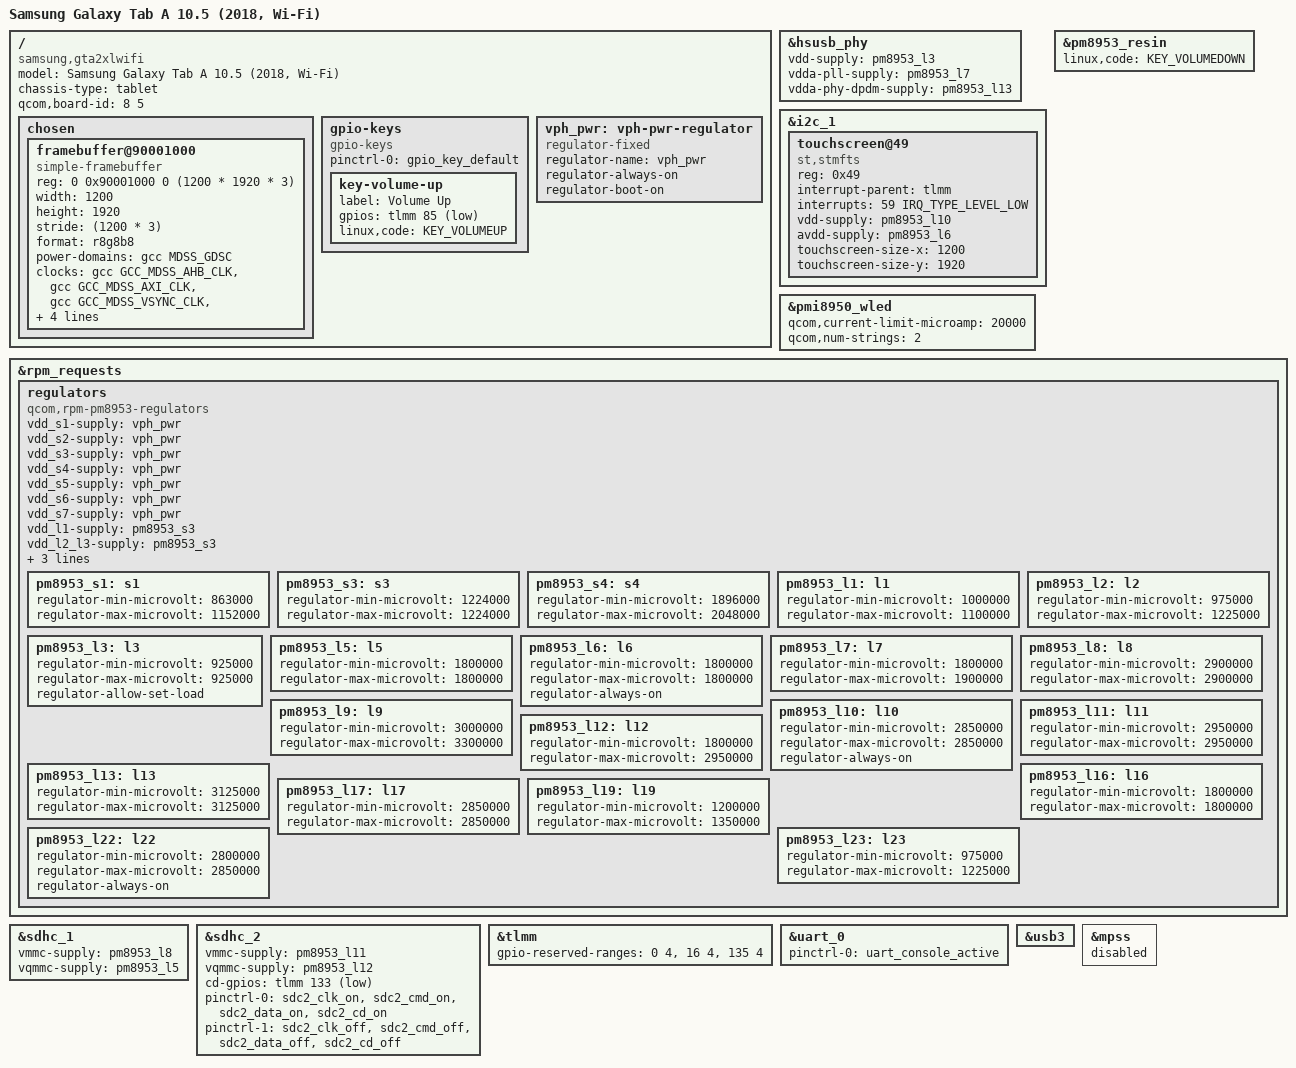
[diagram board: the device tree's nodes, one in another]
// SPDX-License-Identifier: GPL-2.0-only
/*
 * Samsung Galaxy Tab A 10.5 (2018, Wi-Fi) — "gta2xlwifi"
 * SoC: Qualcomm SDM450 / MSM8953 family
 *
 * Initial mainline device tree. Values ported from the downstream
 * Android dts (arch/arm/boot/dts/samsung/sdm450/*gta2xlwifi*).
 * Sections marked TODO still need verification on real hardware.
 */

/dts-v1/;

#include "msm8953.dtsi"
#include "pm8953.dtsi"
#include "pmi8950.dtsi"

/ {
	model = "Samsung Galaxy Tab A 10.5 (2018, Wi-Fi)";
	compatible = "samsung,gta2xlwifi", "qcom,msm8953";
	chassis-type = "tablet";

	/* TODO: confirm against lk2nd; downstream used qcom,board-id = <8 5> */
	qcom,board-id = <8 5>;

	chosen {
		#address-cells = <2>;
		#size-cells = <2>;
		ranges;

		/*
		 * Continuous splash framebuffer set up by the bootloader.
		 * Panel is 1200x1920 (WUXGA, Himax HX8279 TV101WUM).
		 * TODO: verify base address from lk2nd / downstream cont_splash.
		 */
		framebuffer@90001000 {
			compatible = "simple-framebuffer";
			reg = <0 0x90001000 0 (1200 * 1920 * 3)>;

			width = <1200>;
			height = <1920>;
			stride = <(1200 * 3)>;
			format = "r8g8b8";

			power-domains = <&gcc MDSS_GDSC>;

			clocks = <&gcc GCC_MDSS_AHB_CLK>,
				 <&gcc GCC_MDSS_AXI_CLK>,
				 <&gcc GCC_MDSS_VSYNC_CLK>,
				 <&gcc GCC_MDSS_MDP_CLK>,
				 <&gcc GCC_MDSS_BYTE0_CLK>,
				 <&gcc GCC_MDSS_PCLK0_CLK>,
				 <&gcc GCC_MDSS_ESC0_CLK>;
		};
	};

	gpio-keys {
		compatible = "gpio-keys";

		pinctrl-names = "default";
		pinctrl-0 = <&gpio_key_default>;

		key-volume-up {
			label = "Volume Up";
			gpios = <&tlmm 85 GPIO_ACTIVE_LOW>;
			linux,code = <KEY_VOLUMEUP>;
		};
		/* Volume Down and Power are handled by the PMIC (see &pm8953_resin
		 * and the pm8953 pon below) */
	};

	vph_pwr: vph-pwr-regulator {
		compatible = "regulator-fixed";
		regulator-name = "vph_pwr";
		regulator-always-on;
		regulator-boot-on;
	};
};

&hsusb_phy {
	vdd-supply = <&pm8953_l3>;
	vdda-pll-supply = <&pm8953_l7>;
	vdda-phy-dpdm-supply = <&pm8953_l13>;

	status = "okay";
};

/* Touchscreen: STMicroelectronics FTS, i2c@78b5000, addr 0x49, IRQ on tlmm 59 */
&i2c_1 {
	status = "okay";

	touchscreen@49 {
		compatible = "st,stmfts";
		reg = <0x49>;

		interrupt-parent = <&tlmm>;
		interrupts = <59 IRQ_TYPE_LEVEL_LOW>;

		/* TODO: confirm regulator rails (downstream: tsp_avdd ~2.9V, tsp_dvdd 1.8V) */
		vdd-supply = <&pm8953_l10>;
		avdd-supply = <&pm8953_l6>;

		touchscreen-size-x = <1200>;
		touchscreen-size-y = <1920>;
	};
};

/* Volume Down */
&pm8953_resin {
	linux,code = <KEY_VOLUMEDOWN>;
	status = "okay";
};

/* Display backlight (WLED) */
&pmi8950_wled {
	qcom,current-limit-microamp = <20000>;
	qcom,num-strings = <2>;

	status = "okay";
};

&rpm_requests {
	regulators {
		compatible = "qcom,rpm-pm8953-regulators";

		vdd_s1-supply = <&vph_pwr>;
		vdd_s2-supply = <&vph_pwr>;
		vdd_s3-supply = <&vph_pwr>;
		vdd_s4-supply = <&vph_pwr>;
		vdd_s5-supply = <&vph_pwr>;
		vdd_s6-supply = <&vph_pwr>;
		vdd_s7-supply = <&vph_pwr>;
		vdd_l1-supply = <&pm8953_s3>;
		vdd_l2_l3-supply = <&pm8953_s3>;
		vdd_l4_l5_l6_l7_l16_l19-supply = <&pm8953_s4>;
		vdd_l8_l11_l12_l13_l14_l15-supply = <&vph_pwr>;
		vdd_l9_l10_l17_l18_l22-supply = <&vph_pwr>;

		pm8953_s1: s1 {
			regulator-min-microvolt = <863000>;
			regulator-max-microvolt = <1152000>;
		};

		pm8953_s3: s3 {
			regulator-min-microvolt = <1224000>;
			regulator-max-microvolt = <1224000>;
		};

		pm8953_s4: s4 {
			regulator-min-microvolt = <1896000>;
			regulator-max-microvolt = <2048000>;
		};

		pm8953_l1: l1 {
			regulator-min-microvolt = <1000000>;
			regulator-max-microvolt = <1100000>;
		};

		pm8953_l2: l2 {
			regulator-min-microvolt = <975000>;
			regulator-max-microvolt = <1225000>;
		};

		pm8953_l3: l3 {
			regulator-min-microvolt = <925000>;
			regulator-max-microvolt = <925000>;
			regulator-allow-set-load;
		};

		pm8953_l5: l5 {
			regulator-min-microvolt = <1800000>;
			regulator-max-microvolt = <1800000>;
		};

		pm8953_l6: l6 {
			regulator-min-microvolt = <1800000>;
			regulator-max-microvolt = <1800000>;
			regulator-always-on;
		};

		pm8953_l7: l7 {
			regulator-min-microvolt = <1800000>;
			regulator-max-microvolt = <1900000>;
		};

		pm8953_l8: l8 {
			regulator-min-microvolt = <2900000>;
			regulator-max-microvolt = <2900000>;
		};

		pm8953_l9: l9 {
			regulator-min-microvolt = <3000000>;
			regulator-max-microvolt = <3300000>;
		};

		pm8953_l10: l10 {
			regulator-min-microvolt = <2850000>;
			regulator-max-microvolt = <2850000>;
			regulator-always-on;
		};

		pm8953_l11: l11 {
			regulator-min-microvolt = <2950000>;
			regulator-max-microvolt = <2950000>;
		};

		pm8953_l12: l12 {
			regulator-min-microvolt = <1800000>;
			regulator-max-microvolt = <2950000>;
		};

		pm8953_l13: l13 {
			regulator-min-microvolt = <3125000>;
			regulator-max-microvolt = <3125000>;
		};

		pm8953_l16: l16 {
			regulator-min-microvolt = <1800000>;
			regulator-max-microvolt = <1800000>;
		};

		pm8953_l17: l17 {
			regulator-min-microvolt = <2850000>;
			regulator-max-microvolt = <2850000>;
		};

		pm8953_l19: l19 {
			regulator-min-microvolt = <1200000>;
			regulator-max-microvolt = <1350000>;
		};

		pm8953_l22: l22 {
			regulator-min-microvolt = <2800000>;
			regulator-max-microvolt = <2850000>;
			regulator-always-on;
		};

		pm8953_l23: l23 {
			regulator-min-microvolt = <975000>;
			regulator-max-microvolt = <1225000>;
		};
	};
};

/* eMMC */
&sdhc_1 {
	vmmc-supply = <&pm8953_l8>;
	vqmmc-supply = <&pm8953_l5>;

	status = "okay";
};

/* microSD */
&sdhc_2 {
	vmmc-supply = <&pm8953_l11>;
	vqmmc-supply = <&pm8953_l12>;

	/* TODO: confirm card-detect GPIO for this board */
	cd-gpios = <&tlmm 133 GPIO_ACTIVE_LOW>;

	pinctrl-names = "default", "sleep";
	pinctrl-0 = <&sdc2_clk_on &sdc2_cmd_on &sdc2_data_on &sdc2_cd_on>;
	pinctrl-1 = <&sdc2_clk_off &sdc2_cmd_off &sdc2_data_off &sdc2_cd_off>;

	status = "okay";
};

&tlmm {
	gpio-reserved-ranges = <0 4>, <16 4>, <135 4>;
};

/* Serial console (via lk2nd) */
&uart_0 {
	pinctrl-names = "default";
	pinctrl-0 = <&uart_console_active>;

	status = "okay";
};

&usb3 {
	/* Node already defaults to peripheral via role-switch-default-mode */
	status = "okay";
};

/*
 * Wi-Fi only tablet — no cellular modem present.
 * Keep the modem remoteproc disabled.
 */
&mpss {
	status = "disabled";
};

/*
 * TODO (next bring-up steps):
 *  - DSI panel: Himax HX8279 TV101WUM WUXGA (1200x1920), reset gpio tlmm 50,
 *    extra power gpio tlmm 35 (1.5V), panel power via ISL98608 @ i2c 0x29.
 *    Needs &mdss / &dsi0 / panel node + generated panel driver.
 *  - Wi-Fi/BT: &wcnss (pronto) — enable once regulators/iris are mapped.
 *  - Sensors (i2c-gpio), vibrator, charger/fuel-gauge (s2mu004/s2mm005).
 */
